# ATSAM4S16B device description
Architecture: CORTEX-M4; Family: SAM4; Series: SAM4S
Registers are 32-bit, read-write, no defined reset value unless marked. A register's access mark holds for its fields unless they carry their own. Offsets are from the block's base; [hi:lo] are bit positions; {n}, {i} and the like mark numbered series.

## CRCCU — Cyclic Redundancy Check Calculation Unit
Instances: CRCCU 0x40044000
0x00 CRCCU_DSCR — CRCCU Descriptor Base Register
  [31:9] DSCR — Descriptor Base Address
0x08 CRCCU_DMA_EN wo — CRCCU DMA Enable Register
  [0] DMAEN — DMA Enable
0x0C CRCCU_DMA_DIS wo — CRCCU DMA Disable Register
  [0] DMADIS — DMA Disable
0x10 CRCCU_DMA_SR ro — CRCCU DMA Status Register
  [0] DMASR — DMA Status
0x14 CRCCU_DMA_IER wo — CRCCU DMA Interrupt Enable Register
  [0] DMAIER — Interrupt Enable
0x18 CRCCU_DMA_IDR wo — CRCCU DMA Interrupt Disable Register
  [0] DMAIDR — Interrupt Disable
0x1C CRCCU_DMA_IMR ro — CRCCU DMA Interrupt Mask Register
  [0] DMAIMR — Interrupt Mask
0x20 CRCCU_DMA_ISR ro — CRCCU DMA Interrupt Status Register
  [0] DMAISR — Interrupt Status
0x34 CRCCU_CR wo — CRCCU Control Register
  [0] RESET — CRC Computation Reset
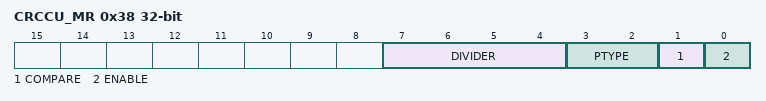
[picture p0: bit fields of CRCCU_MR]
0x38 CRCCU_MR — CRCCU Mode Register
  [7:4] DIVIDER — Request Divider
  [3:2] PTYPE — Primitive Polynomial
    0=CCITT8023 (Polynom 0x04C11DB7); 1=CASTAGNOLI (Polynom 0x1EDC6F41); 2=CCITT16 (Polynom 0x1021)
  [1] COMPARE — CRC Compare
  [0] ENABLE — CRC Enable
0x3C CRCCU_SR ro — CRCCU Status Register
  [31:0] CRC — Cyclic Redundancy Check Value
0x40 CRCCU_IER wo — CRCCU Interrupt Enable Register
  [0] ERRIER — CRC Error Interrupt Enable
0x44 CRCCU_IDR wo — CRCCU Interrupt Disable Register
  [0] ERRIDR — CRC Error Interrupt Disable
0x48 CRCCU_IMR ro — CRCCU Interrupt Mask Register
  [0] ERRIMR — CRC Error Interrupt Mask
0x4C CRCCU_ISR ro — CRCCU Interrupt Status Register
  [0] ERRISR — CRC Error Interrupt Status

## EFC — Embedded Flash Controller
Instances: EFC0 0x400E0A00
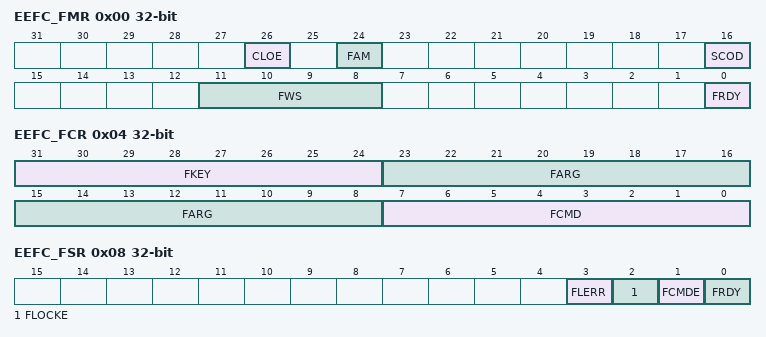
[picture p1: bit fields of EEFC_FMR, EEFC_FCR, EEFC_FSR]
0x00 EEFC_FMR — EEFC Flash Mode Register
  [26] CLOE — Code Loop Optimization Enable
  [24] FAM — Flash Access Mode
  [16] SCOD — Sequential Code Optimization Disable
  [11:8] FWS — Flash Wait State
  [0] FRDY — Flash Ready Interrupt Enable
0x04 EEFC_FCR wo — EEFC Flash Command Register
  [31:24] FKEY — Flash Writing Protection Key
    90=PASSWD (The 0x5A value enables the command defined by the bits of the register. If the field is written with a different value, the write is not performed and no action is started.)
  [23:8] FARG — Flash Command Argument
  [7:0] FCMD — Flash Command
    0=GETD (Get Flash descriptor); 1=WP (Write page); 2=WPL (Write page and lock); 3=EWP (Erase page and write page); 4=EWPL (Erase page and write page then lock); 5=EA (Erase all); 7=EPA (Erase pages); 8=SLB (Set lock bit); 9=CLB (Clear lock bit); 10=GLB (Get lock bit); 11=SGPB (Set GPNVM bit); 12=CGPB (Clear GPNVM bit); 13=GGPB (Get GPNVM bit); 14=STUI (Start read unique identifier); 15=SPUI (Stop read unique identifier); 16=GCALB (Get CALIB bit); 17=ES (Erase sector); 18=WUS (Write user signature); 19=EUS (Erase user signature); 20=STUS (Start read user signature); 21=SPUS (Stop read user signature)
0x08 EEFC_FSR ro — EEFC Flash Status Register
  [3] FLERR — Flash Error Status (cleared when a programming operation starts)
  [2] FLOCKE — Flash Lock Error Status (cleared on read)
  [1] FCMDE — Flash Command Error Status (cleared on read or by writing EEFC_FCR)
  [0] FRDY — Flash Ready Status (cleared when Flash is busy)
0x0C EEFC_FRR ro — EEFC Flash Result Register
  [31:0] FVALUE — Flash Result Value

## GPBR — General Purpose Backup Registers
Instances: GPBR 0x400E1490
{0x0+4i} SYS_GPBR{i} (i=0..7) — General Purpose Backup Register {i}
  [31:0] GPBR_VALUE — Value of GPBR x

## MATRIX — AHB Bus Matrix
Instances: MATRIX 0x400E0200
{0x0+4i} MATRIX_MCFG{i} (i=0..3) — Master Configuration Register {i}
  [2:0] ULBT — Undefined Length Burst Type
    0=INFINITE (No predicted end of burst is generated and therefore INCR bursts coming from this master cannot be broken.); 1=SINGLE (The undefined length burst is treated as a succession of single access allowing rearbitration at each beat of the INCR burst.); 2=FOUR_BEAT (The undefined length burst is split into a 4-beat bursts allowing rearbitration at each 4-beat burst end.); 3=EIGHT_BEAT (The undefined length burst is split into 8-beat bursts allowing rearbitration at each 8-beat burst end.); 4=SIXTEEN_BEAT (The undefined length burst is split into 16-beat bursts allowing rearbitration at each 16-beat burst end.)
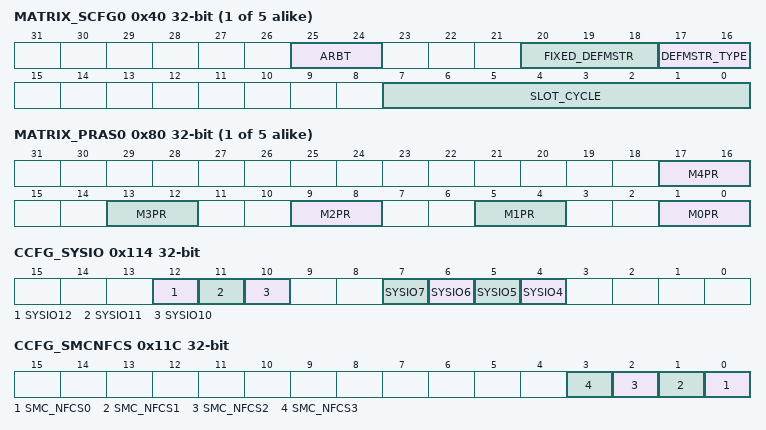
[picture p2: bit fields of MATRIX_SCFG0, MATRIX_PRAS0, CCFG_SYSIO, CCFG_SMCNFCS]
{0x40+4i} MATRIX_SCFG{i} (i=0..4) — Slave Configuration Register {i}
  [25:24] ARBT — Arbitration Type
    0=ROUND_ROBIN (Round-robin arbitration); 1=FIXED_PRIORITY (Fixed priority arbitration)
  [20:18] FIXED_DEFMSTR — Fixed Default Master
  [17:16] DEFMSTR_TYPE — Default Master Type
    0=NO_DEFAULT (At the end of current slave access, if no other master request is pending, the slave is disconnected from all masters.This results in having a one cycle latency for the first access of a burst transfer or for a single access.); 1=LAST (At the end of current slave access, if no other master request is pending, the slave stays connected to the last master having accessed it.This results in not having the one cycle latency when the last master tries to access the slave again.); 2=FIXED (At the end of the current slave access, if no other master request is pending, the slave connects to the fixed master the number that has been written in the FIXED_DEFMSTR field.This results in not having the one cycle latency when the fixed master tries to access the slave again.)
  [7:0] SLOT_CYCLE — Maximum Number of Allowed Cycles for a Burst
{0x80+8i} MATRIX_PRAS{i} (i=0..4) — Priority Register A for Slave {i}
  [4n+1:4n] M{n}PR (n=0..4) — Master {n} Priority
0x114 CCFG_SYSIO — System I/O Configuration register
  [12] SYSIO12 — PB12 or ERASE Assignment
  [11] SYSIO11 — PB11 or DDP Assignment
  [10] SYSIO10 — PB10 or DDM Assignment
  [7] SYSIO7 — PB7 or TCK/SWCLK Assignment
  [6] SYSIO6 — PB6 or TMS/SWDIO Assignment
  [5] SYSIO5 — PB5 or TDO/TRACESWO Assignment
  [4] SYSIO4 — PB4 or TDI Assignment
0x11C CCFG_SMCNFCS — SMC Chip Select NAND Flash Assignment Register
  [n] SMC_NFCS{n} (n=0..3) — SMC NAND Flash Chip Select {n} Assignment
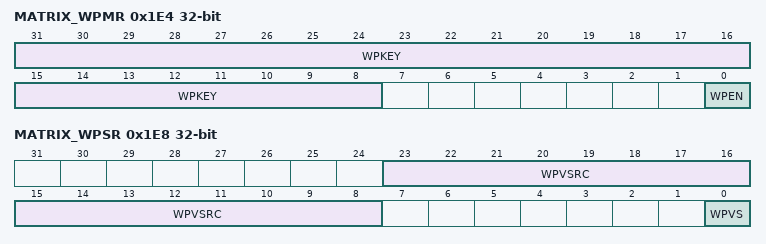
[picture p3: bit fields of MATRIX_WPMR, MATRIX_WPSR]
0x1E4 MATRIX_WPMR — Write Protection Mode Register
  [31:8] WPKEY — Write Protect Key
    0x4D4154=PASSWD (Writing any other value in this field aborts the write operation of the WPEN bit. Always reads as 0.)
  [0] WPEN — Write Protection Enable
0x1E8 MATRIX_WPSR ro — Write Protection Status Register
  [23:8] WPVSRC — Write Protection Violation Source
  [0] WPVS — Write Protection Violation Status

## Notices in the file
SAM Software Package License
Copyright (c) %copyright_year%, Atmel Corporation
All rights reserved.
Redistribution and use in source and binary forms, with or without
modification, are permitted provided that the following condition is met:
- Redistributions of source code must retain the above copyright notice,
this list of conditions and the disclaimer below.
Atmel's name may not be used to endorse or promote products derived from
this software without specific prior written permission.
DISCLAIMER:  THIS SOFTWARE IS PROVIDED BY ATMEL "AS IS" AND ANY EXPRESS OR
IMPLIED WARRANTIES, INCLUDING, BUT NOT LIMITED TO, THE IMPLIED WARRANTIES OF
MERCHANTABILITY, FITNESS FOR A PARTICULAR PURPOSE AND NON-INFRINGEMENT ARE
DISCLAIMED. IN NO EVENT SHALL ATMEL BE LIABLE FOR ANY DIRECT, INDIRECT,
INCIDENTAL, SPECIAL, EXEMPLARY, OR CONSEQUENTIAL DAMAGES (INCLUDING, BUT NOT
LIMITED TO, PROCUREMENT OF SUBSTITUTE GOODS OR SERVICES; LOSS OF USE, DATA,
OR PROFITS; OR BUSINESS INTERRUPTION) HOWEVER CAUSED AND ON ANY THEORY OF
LIABILITY, WHETHER IN CONTRACT, STRICT LIABILITY, OR TORT (INCLUDING
NEGLIGENCE OR OTHERWISE) ARISING IN ANY WAY OUT OF THE USE OF THIS SOFTWARE,
EVEN IF ADVISED OF THE POSSIBILITY OF SUCH DAMAGE.
